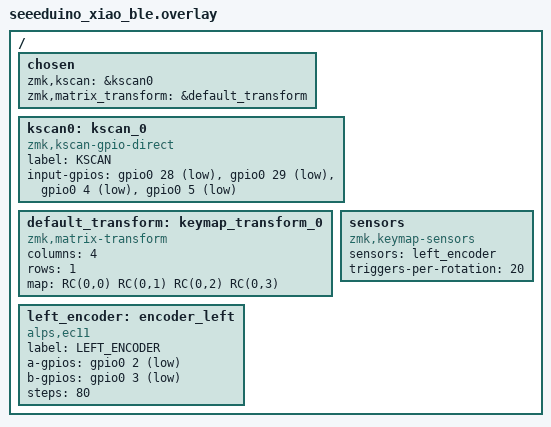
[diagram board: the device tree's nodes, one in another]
#include <dt-bindings/zmk/matrix_transform.h>
#include <dt-bindings/gpio/gpio.h>

/ {
    chosen {
        zmk,kscan = &kscan0;
        zmk,matrix_transform = &default_transform;
    };

    kscan0: kscan_0 {
        compatible = "zmk,kscan-gpio-direct";
        label = "KSCAN";
        input-gpios
            = <&gpio0 28 (GPIO_ACTIVE_LOW | GPIO_PULL_UP)> // 엔코더 푸시 (D2)
            , <&gpio0 29 (GPIO_ACTIVE_LOW | GPIO_PULL_UP)> // 버튼 1 (D3)
            , <&gpio0 4  (GPIO_ACTIVE_LOW | GPIO_PULL_UP)> // 버튼 2 (D4)
            , <&gpio0 5  (GPIO_ACTIVE_LOW | GPIO_PULL_UP)> // 버튼 3 (D5) - 추가됨!
            ;
    };

    default_transform: keymap_transform_0 {
        compatible = "zmk,matrix-transform";
        columns = <4>; // 3개에서 4개로 늘림!
        rows = <1>;
        map = <
            RC(0,0) RC(0,1) RC(0,2) RC(0,3) // RC(0,3) 추가됨!
        >;
    };

left_encoder: encoder_left {
        compatible = "alps,ec11";
        label = "LEFT_ENCODER";
        a-gpios = <&gpio0 2 (GPIO_ACTIVE_LOW | GPIO_PULL_UP)>;
        b-gpios = <&gpio0 3 (GPIO_ACTIVE_LOW | GPIO_PULL_UP)>;
        
        // 딸깍(Detent) 한 칸당 신호가 4개니까, 
        // 20칸(한 바퀴) * 4 = 80으로 스펙을 정의합니다.
        steps = <80>; 
        
        status = "okay";
    };

    sensors: sensors {
        compatible = "zmk,keymap-sensors";
        sensors = <&left_encoder>;
        triggers-per-rotation = <20>;
    };
};
